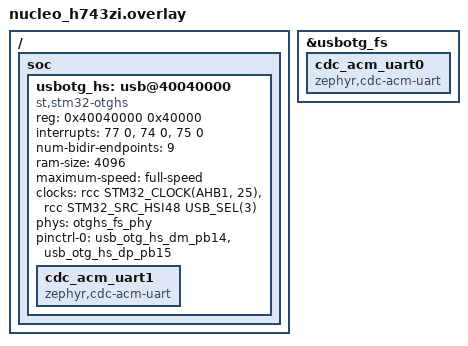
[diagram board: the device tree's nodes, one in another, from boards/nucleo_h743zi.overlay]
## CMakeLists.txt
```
# SPDX-License-Identifier: GPL-3.0-or-later
cmake_minimum_required(VERSION 3.20.0)
find_package(Zephyr REQUIRED HINTS $ENV{ZEPHYR_BASE})
project(usb2_derisk)
target_sources(app PRIVATE src/main.c)
```

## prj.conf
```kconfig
# De-risk build 2: two USB device controllers (OTG FS + OTG HS in full-speed mode) in one image
CONFIG_USB_DEVICE_STACK_NEXT=y
CONFIG_USBD_CDC_ACM_CLASS=y
CONFIG_SERIAL=y
CONFIG_UART_LINE_CTRL=y
CONFIG_LOG=y
CONFIG_USBD_LOG_LEVEL_ERR=y
CONFIG_UDC_DRIVER_LOG_LEVEL_ERR=y
```

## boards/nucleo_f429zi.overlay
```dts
/* SPDX-License-Identifier: GPL-3.0-or-later
 * STM32F429 already defines usbotg_hs (stm32f405.dtsi) with the embedded full-speed PHY.
 */
&usbotg_hs {
	pinctrl-0 = <&usb_otg_hs_dm_pb14 &usb_otg_hs_dp_pb15>;
	pinctrl-names = "default";
	status = "okay";

	cdc_acm_uart1: cdc_acm_uart1 {
		compatible = "zephyr,cdc-acm-uart";
	};
};

&usbotg_fs {
	cdc_acm_uart0: cdc_acm_uart0 {
		compatible = "zephyr,cdc-acm-uart";
	};
};
```

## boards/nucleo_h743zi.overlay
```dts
/* SPDX-License-Identifier: GPL-3.0-or-later
 *
 * STM32H743 defines only usbotg_fs in the SoC dtsi (usbotg_hs exists for H723, H745, H7A3).
 * This node is modelled on dts/arm/st/h7/stm32h723.dtsi, set to full speed on the
 * embedded PHY (PB14/PB15). Address, IRQ numbers and clock bit are the H723 values;
 * they must be checked against the H743 reference manual (RM0433) before hardware use.
 */
/ {
	soc {
		usbotg_hs: usb@40040000 {
			compatible = "st,stm32-otghs";
			reg = <0x40040000 0x40000>;
			interrupts = <77 0>, <74 0>, <75 0>;
			interrupt-names = "otghs", "ep1_out", "ep1_in";
			num-bidir-endpoints = <9>;
			ram-size = <4096>;
			maximum-speed = "full-speed";
			clocks = <&rcc STM32_CLOCK(AHB1, 25)>,
				 <&rcc STM32_SRC_HSI48 USB_SEL(3)>;
			phys = <&otghs_fs_phy>;
			pinctrl-0 = <&usb_otg_hs_dm_pb14 &usb_otg_hs_dp_pb15>;
			pinctrl-names = "default";
			status = "okay";

			cdc_acm_uart1: cdc_acm_uart1 {
				compatible = "zephyr,cdc-acm-uart";
			};
		};
	};
};

&usbotg_fs {
	cdc_acm_uart0: cdc_acm_uart0 {
		compatible = "zephyr,cdc-acm-uart";
	};
};
```

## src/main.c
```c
/*
 * SPDX-License-Identifier: GPL-3.0-or-later
 *
 * De-risk build 2 for "Flip my flipper": bring up TWO independent USB device
 * contexts in one Zephyr image. usbd_fs sits on the OTG FS controller (the
 * USB-C console port), usbd_hs on the OTG HS controller running in full-speed
 * mode on its embedded PHY (PB14/PB15, reserved for the Linux link).
 * Build-level proof only: nothing here has run on hardware.
 */
#include <zephyr/kernel.h>
#include <zephyr/device.h>
#include <zephyr/usb/usbd.h>
#include <zephyr/logging/log.h>

LOG_MODULE_REGISTER(usb2_derisk, LOG_LEVEL_INF);

#define VID 0x2fe3 /* Zephyr test VID, for samples only */

USBD_DEVICE_DEFINE(usbd_fs, DEVICE_DT_GET(DT_NODELABEL(usbotg_fs)), VID, 0x0001);
USBD_DEVICE_DEFINE(usbd_hs, DEVICE_DT_GET(DT_NODELABEL(usbotg_hs)), VID, 0x0002);

/* A descriptor node can only be linked into one context, so each context gets its own set */
USBD_DESC_LANG_DEFINE(lang_fs);
USBD_DESC_MANUFACTURER_DEFINE(mfr_fs, "Synnefo");
USBD_DESC_PRODUCT_DEFINE(prod_fs, "Synnefo console (OTG FS)");
USBD_DESC_CONFIG_DEFINE(cfgdesc_fs, "FS config");
USBD_CONFIGURATION_DEFINE(config_fs, 0, 100, &cfgdesc_fs);

USBD_DESC_LANG_DEFINE(lang_hs);
USBD_DESC_MANUFACTURER_DEFINE(mfr_hs, "Synnefo");
USBD_DESC_PRODUCT_DEFINE(prod_hs, "Synnefo link (OTG HS, FS mode)");
USBD_DESC_CONFIG_DEFINE(cfgdesc_hs, "HS-port config");
USBD_CONFIGURATION_DEFINE(config_hs, 0, 100, &cfgdesc_hs);

static int bring_up(struct usbd_context *ctx, struct usbd_desc_node *lang,
		    struct usbd_desc_node *mfr, struct usbd_desc_node *prod,
		    struct usbd_config_node *cfg, const char *class_name)
{
	int err;

	err = usbd_add_descriptor(ctx, lang);
	if (err) {
		return err;
	}
	err = usbd_add_descriptor(ctx, mfr);
	if (err) {
		return err;
	}
	err = usbd_add_descriptor(ctx, prod);
	if (err) {
		return err;
	}
	err = usbd_add_configuration(ctx, USBD_SPEED_FS, cfg);
	if (err) {
		return err;
	}
	err = usbd_register_class(ctx, class_name, USBD_SPEED_FS, 1);
	if (err) {
		return err;
	}
	usbd_device_set_code_triple(ctx, USBD_SPEED_FS, USB_BCC_MISCELLANEOUS, 0x02, 0x01);
	err = usbd_init(ctx);
	if (err) {
		return err;
	}
	return usbd_enable(ctx);
}

int main(void)
{
	int err;

	err = bring_up(&usbd_fs, &lang_fs, &mfr_fs, &prod_fs, &config_fs, "cdc_acm_0");
	LOG_INF("OTG FS context: %d", err);

	err = bring_up(&usbd_hs, &lang_hs, &mfr_hs, &prod_hs, &config_hs, "cdc_acm_1");
	LOG_INF("OTG HS (FS mode) context: %d", err);

	return 0;
}
```
